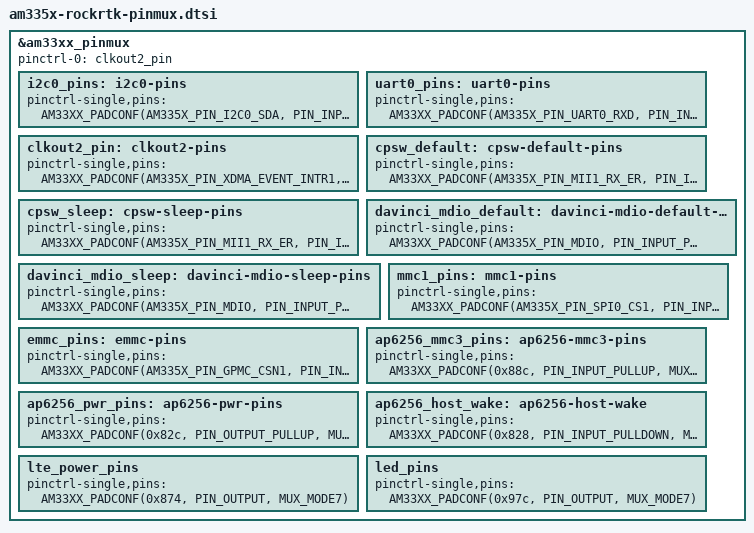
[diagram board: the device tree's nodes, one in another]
&am33xx_pinmux {
	pinctrl-names = "default";
	pinctrl-0 = <&clkout2_pin>;


	i2c0_pins: i2c0-pins {
		pinctrl-single,pins = <
			AM33XX_PADCONF(AM335X_PIN_I2C0_SDA, PIN_INPUT_PULLUP, MUX_MODE0)	/* i2c0_sda.i2c0_sda */
			AM33XX_PADCONF(AM335X_PIN_I2C0_SCL, PIN_INPUT_PULLUP, MUX_MODE0)	/* i2c0_scl.i2c0_scl */
		>;
	};

	uart0_pins: uart0-pins {
		pinctrl-single,pins = <
			AM33XX_PADCONF(AM335X_PIN_UART0_RXD, PIN_INPUT_PULLUP, MUX_MODE0)
			AM33XX_PADCONF(AM335X_PIN_UART0_TXD, PIN_OUTPUT_PULLDOWN, MUX_MODE0)
		>;
	};

	clkout2_pin: clkout2-pins {
		pinctrl-single,pins = <
			AM33XX_PADCONF(AM335X_PIN_XDMA_EVENT_INTR1, PIN_OUTPUT_PULLDOWN, MUX_MODE3)	/* xdma_event_intr1.clkout2 */
		>;
	};

	cpsw_default: cpsw-default-pins {
		pinctrl-single,pins = <
			/* Slave 1 */
			AM33XX_PADCONF(AM335X_PIN_MII1_RX_ER, PIN_INPUT_PULLUP, MUX_MODE0)
			AM33XX_PADCONF(AM335X_PIN_MII1_TX_EN, PIN_OUTPUT_PULLDOWN, MUX_MODE0)
			AM33XX_PADCONF(AM335X_PIN_MII1_RX_DV, PIN_INPUT_PULLUP, MUX_MODE0)
			AM33XX_PADCONF(AM335X_PIN_MII1_TXD3, PIN_OUTPUT_PULLDOWN, MUX_MODE0)
			AM33XX_PADCONF(AM335X_PIN_MII1_TXD2, PIN_OUTPUT_PULLDOWN, MUX_MODE0)
			AM33XX_PADCONF(AM335X_PIN_MII1_TXD1, PIN_OUTPUT_PULLDOWN, MUX_MODE0)
			AM33XX_PADCONF(AM335X_PIN_MII1_TXD0, PIN_OUTPUT_PULLDOWN, MUX_MODE0)
			AM33XX_PADCONF(AM335X_PIN_MII1_TX_CLK, PIN_INPUT_PULLUP, MUX_MODE0)
			AM33XX_PADCONF(AM335X_PIN_MII1_RX_CLK, PIN_INPUT_PULLUP, MUX_MODE0)
			AM33XX_PADCONF(AM335X_PIN_MII1_RXD3, PIN_INPUT_PULLUP, MUX_MODE0)
			AM33XX_PADCONF(AM335X_PIN_MII1_RXD2, PIN_INPUT_PULLUP, MUX_MODE0)
			AM33XX_PADCONF(AM335X_PIN_MII1_RXD1, PIN_INPUT_PULLUP, MUX_MODE0)
			AM33XX_PADCONF(AM335X_PIN_MII1_RXD0, PIN_INPUT_PULLUP, MUX_MODE0)
		>;
	};

	cpsw_sleep: cpsw-sleep-pins {
		pinctrl-single,pins = <
			/* Slave 1 reset value */
			AM33XX_PADCONF(AM335X_PIN_MII1_RX_ER, PIN_INPUT_PULLDOWN, MUX_MODE7)
			AM33XX_PADCONF(AM335X_PIN_MII1_TX_EN, PIN_INPUT_PULLDOWN, MUX_MODE7)
			AM33XX_PADCONF(AM335X_PIN_MII1_RX_DV, PIN_INPUT_PULLDOWN, MUX_MODE7)
			AM33XX_PADCONF(AM335X_PIN_MII1_TXD3, PIN_INPUT_PULLDOWN, MUX_MODE7)
			AM33XX_PADCONF(AM335X_PIN_MII1_TXD2, PIN_INPUT_PULLDOWN, MUX_MODE7)
			AM33XX_PADCONF(AM335X_PIN_MII1_TXD1, PIN_INPUT_PULLDOWN, MUX_MODE7)
			AM33XX_PADCONF(AM335X_PIN_MII1_TXD0, PIN_INPUT_PULLDOWN, MUX_MODE7)
			AM33XX_PADCONF(AM335X_PIN_MII1_TX_CLK, PIN_INPUT_PULLDOWN, MUX_MODE7)
			AM33XX_PADCONF(AM335X_PIN_MII1_RX_CLK, PIN_INPUT_PULLDOWN, MUX_MODE7)
			AM33XX_PADCONF(AM335X_PIN_MII1_RXD3, PIN_INPUT_PULLDOWN, MUX_MODE7)
			AM33XX_PADCONF(AM335X_PIN_MII1_RXD2, PIN_INPUT_PULLDOWN, MUX_MODE7)
			AM33XX_PADCONF(AM335X_PIN_MII1_RXD1, PIN_INPUT_PULLDOWN, MUX_MODE7)
			AM33XX_PADCONF(AM335X_PIN_MII1_RXD0, PIN_INPUT_PULLDOWN, MUX_MODE7)
		>;
	};

	davinci_mdio_default: davinci-mdio-default-pins {
		pinctrl-single,pins = <
			/* MDIO */
			AM33XX_PADCONF(AM335X_PIN_MDIO, PIN_INPUT_PULLUP | SLEWCTRL_FAST, MUX_MODE0)
			AM33XX_PADCONF(AM335X_PIN_MDC, PIN_OUTPUT_PULLUP, MUX_MODE0)
			/* Added to support GPIO controlled PHY reset */
			AM33XX_PADCONF(AM335X_PIN_UART0_CTSN, PIN_OUTPUT_PULLUP, MUX_MODE7)
		>;
	};

	davinci_mdio_sleep: davinci-mdio-sleep-pins {
		pinctrl-single,pins = <
			/* MDIO reset value */
			AM33XX_PADCONF(AM335X_PIN_MDIO, PIN_INPUT_PULLDOWN, MUX_MODE7)
			AM33XX_PADCONF(AM335X_PIN_MDC, PIN_INPUT_PULLDOWN, MUX_MODE7)
			/* Added to support GPIO controlled PHY reset */
			AM33XX_PADCONF(AM335X_PIN_UART0_CTSN, PIN_INPUT_PULLDOWN, MUX_MODE7)
		>;
	};

	mmc1_pins: mmc1-pins {
		pinctrl-single,pins = <
			AM33XX_PADCONF(AM335X_PIN_SPI0_CS1, PIN_INPUT, MUX_MODE7)		/* spio0_cs1.gpio0_6 */
			AM33XX_PADCONF(AM335X_PIN_MMC0_DAT0, PIN_INPUT_PULLUP, MUX_MODE0)
			AM33XX_PADCONF(AM335X_PIN_MMC0_DAT1, PIN_INPUT_PULLUP, MUX_MODE0)
			AM33XX_PADCONF(AM335X_PIN_MMC0_DAT2, PIN_INPUT_PULLUP, MUX_MODE0)
			AM33XX_PADCONF(AM335X_PIN_MMC0_DAT3, PIN_INPUT_PULLUP, MUX_MODE0)
			AM33XX_PADCONF(AM335X_PIN_MMC0_CMD, PIN_INPUT_PULLUP, MUX_MODE0)
			AM33XX_PADCONF(AM335X_PIN_MMC0_CLK, PIN_INPUT_PULLUP, MUX_MODE0)
		>;
	};

	emmc_pins: emmc-pins {
		pinctrl-single,pins = <
			AM33XX_PADCONF(AM335X_PIN_GPMC_CSN1, PIN_INPUT_PULLUP, MUX_MODE2) /* gpmc_csn1.mmc1_clk */
			AM33XX_PADCONF(AM335X_PIN_GPMC_CSN2, PIN_INPUT_PULLUP, MUX_MODE2) /* gpmc_csn2.mmc1_cmd */
			AM33XX_PADCONF(AM335X_PIN_GPMC_AD0, PIN_INPUT_PULLUP, MUX_MODE1) /* gpmc_ad0.mmc1_dat0 */
			AM33XX_PADCONF(AM335X_PIN_GPMC_AD1, PIN_INPUT_PULLUP, MUX_MODE1) /* gpmc_ad1.mmc1_dat1 */
			AM33XX_PADCONF(AM335X_PIN_GPMC_AD2, PIN_INPUT_PULLUP, MUX_MODE1) /* gpmc_ad2.mmc1_dat2 */
			AM33XX_PADCONF(AM335X_PIN_GPMC_AD3, PIN_INPUT_PULLUP, MUX_MODE1) /* gpmc_ad3.mmc1_dat3 */
			AM33XX_PADCONF(AM335X_PIN_GPMC_AD4, PIN_INPUT_PULLUP, MUX_MODE1) /* gpmc_ad4.mmc1_dat4 */
			AM33XX_PADCONF(AM335X_PIN_GPMC_AD5, PIN_INPUT_PULLUP, MUX_MODE1) /* gpmc_ad5.mmc1_dat5 */
			AM33XX_PADCONF(AM335X_PIN_GPMC_AD6, PIN_INPUT_PULLUP, MUX_MODE1) /* gpmc_ad6.mmc1_dat6 */
			AM33XX_PADCONF(AM335X_PIN_GPMC_AD7, PIN_INPUT_PULLUP, MUX_MODE1) /* gpmc_ad7.mmc1_dat7 */
		>;
	};

    /* SDIO AP6256 (MMC3 / mmc2_*) */
    ap6256_mmc3_pins: ap6256-mmc3-pins {
        pinctrl-single,pins = <
			AM33XX_PADCONF(0x88c, PIN_INPUT_PULLUP, MUX_MODE3) /* (V12) gpmc_clk.mmc2_clk */
			AM33XX_PADCONF(0x888, PIN_INPUT_PULLUP, MUX_MODE3) /* (T13) gpmc_csn3.mmc2_cmd */
			AM33XX_PADCONF(0x830, PIN_INPUT_PULLUP, MUX_MODE3) /* (T12) gpmc_ad12.mmc2_dat0 */
			AM33XX_PADCONF(0x834, PIN_INPUT_PULLUP, MUX_MODE3) /* (R12) gpmc_ad13.mmc2_dat1 */
			AM33XX_PADCONF(0x838, PIN_INPUT_PULLUP, MUX_MODE3) /* (V13) gpmc_ad14.mmc2_dat2 */
			AM33XX_PADCONF(0x83c, PIN_INPUT_PULLUP, MUX_MODE3) /* (U13) gpmc_ad15.mmc2_dat3 */
        >;
    };

    /* GPIO WL_REG_ON (reset) */
    ap6256_pwr_pins: ap6256-pwr-pins { 
        pinctrl-single,pins = <
            AM33XX_PADCONF(0x82c, PIN_OUTPUT_PULLUP, MUX_MODE7) /* gpmc_ad11 -> gpio0[27] */
        >;
    };

	/* GPIO WL_HOST_WAKE (interrupt to host) */
	ap6256_host_wake: ap6256-host-wake {
		pinctrl-single,pins = <
			AM33XX_PADCONF(0x828, PIN_INPUT_PULLDOWN, MUX_MODE7) /* gpmc_ad10 -> gpio0[26] */
		>;
	};

	/* GPIO LTE_POWER (power on/off) */
	lte_power_pins: lte_power_pins {
        pinctrl-single,pins = <
            AM33XX_PADCONF(0x874, PIN_OUTPUT, MUX_MODE7) /* (U17) gpmc_wpn.gpio0[31] -> gpio0[31] */
        >;
    };

    /* GPIO LED */
	led_pins: led_pins {
        pinctrl-single,pins = <
            AM33XX_PADCONF(0x97c, PIN_OUTPUT, MUX_MODE7)  /* (D17) uart1_rtsn.gpio0[13] -> gpio0[13] */ 
        >;
    };
};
